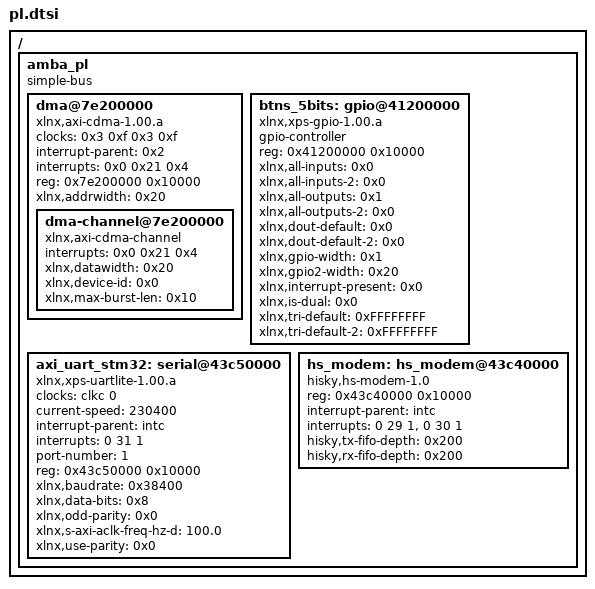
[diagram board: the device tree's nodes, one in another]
/*
 * CAUTION: This file is automatically generated by Xilinx.
 * Version:  
 * Today is: Wed Jan 15 12:55:47 2020
 */

/include/ "pcw.dtsi"

/ {
	amba_pl: amba_pl {
		#address-cells = <1>;
		#size-cells = <1>;
		compatible = "simple-bus";
		ranges ;
		
		dma@7e200000 {
			#dma-cells = <0x1>;
			clock-names = "s_axi_lite_aclk", "m_axi_aclk";
			clocks = <0x3 0xf 0x3 0xf>;
			compatible = "xlnx,axi-cdma-1.00.a";
			interrupt-parent = <0x2>;
			interrupts = <0x0 0x21 0x4>;
			reg = <0x7e200000 0x10000>;
			xlnx,addrwidth = <0x20>;

			dma-channel@7e200000 {
				compatible = "xlnx,axi-cdma-channel";
				interrupts = <0x0 0x21 0x4>;
				xlnx,datawidth = <0x20>;
				xlnx,device-id = <0x0>;
				xlnx,max-burst-len = <0x10>;
			};
		};

		btns_5bits: gpio@41200000 {
			#gpio-cells = <2>;
			compatible = "xlnx,xps-gpio-1.00.a";
			gpio-controller ;
			reg = <0x41200000 0x10000>;
			xlnx,all-inputs = <0x0>;
			xlnx,all-inputs-2 = <0x0>;
			xlnx,all-outputs = <0x1>;
			xlnx,all-outputs-2 = <0x0>;
			xlnx,dout-default = <0x0>;
			xlnx,dout-default-2 = <0x0>;
			xlnx,gpio-width = <0x1>;
			xlnx,gpio2-width = <0x20>;
			xlnx,interrupt-present = <0x0>;
			xlnx,is-dual = <0x0>;
			xlnx,tri-default = <0xFFFFFFFF>;
			xlnx,tri-default-2 = <0xFFFFFFFF>;
		};

		axi_uart_stm32: serial@43c50000 {
			clock-names = "ref_clk";
			clocks = <&clkc 0>;
			compatible = "xlnx,xps-uartlite-1.00.a";
			current-speed = <230400>;
			device_type = "serial";
			interrupt-parent = <&intc>;
			interrupts = <0 31 1>;
			port-number = <1>;
			reg = <0x43c50000 0x10000>;
			xlnx,baudrate = <0x38400>;
			xlnx,data-bits = <0x8>;
			xlnx,odd-parity = <0x0>;
			xlnx,s-axi-aclk-freq-hz-d = "100.0";
			xlnx,use-parity = <0x0>;
		};

		hs_modem: hs_modem@43c40000 {
			#interrupt-cells = <2>;
			compatible = "hisky,hs-modem-1.0";
			reg = <0x43c40000 0x10000>;
			
			interrupt-parent = <&intc>;
			//              Rx        Tx
			interrupts = <0 29 1>, <0 30 1>;
			hisky,tx-fifo-depth = <0x200>;
			hisky,rx-fifo-depth = <0x200>;
		};
	
	};
};
